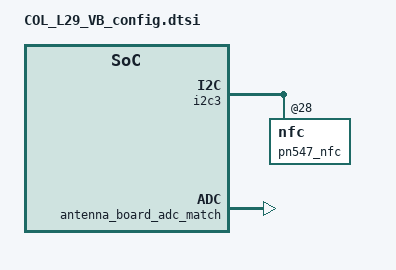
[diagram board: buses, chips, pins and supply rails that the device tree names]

/**
 * Copyright (C) 2014 Hisilicon Ltd.
 *
 *  This program is free software; you can redistribute it and/or modify
 *  it under the terms of the GNU General Public License version 2 as
 *  publishhed by the Free Software Foundation.
 */

/include/ "huawei_antenna_board_match.dtsi"
/include/ "COL_L29_VA_config.dtsi"

/ {
	hisi,boardid = <6 8 2 2>;
	hisi,boardname = "COL_L29_VB";
	hisi,modem_id = <0x39613800>;

	amba: amba {
		i2c3: i2c@FDF0C000 {
			pn547_nfc: nfc@28 {
				nfc_brcm_conf_name = "libnfc-brcm.conf";
				nfc_nxp_name = "libnfc-nxp.conf";
				nfc_card_num = <0x2>;
				nfc_chip_type = "pn551";
			};
		};
	};

	hw_antenna_board_match:hw_antenna_board_match{
		status = "ok";
	};
	antenna_board_adc_match:antenna_board_adc_match{
		status = "ok";
	};
};
